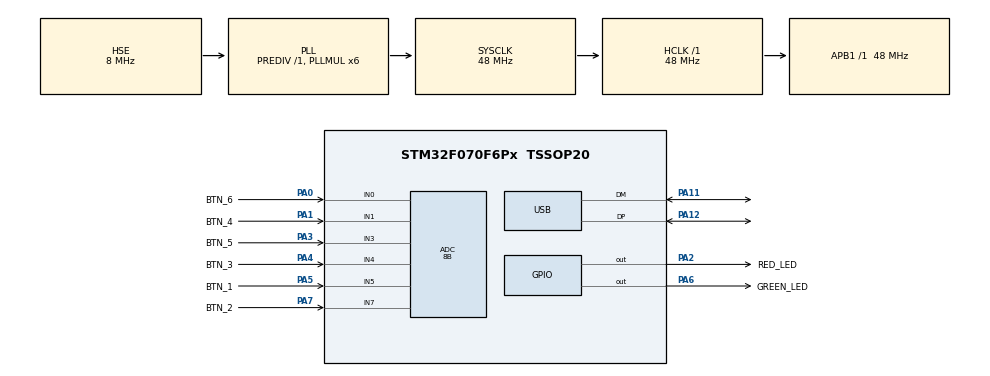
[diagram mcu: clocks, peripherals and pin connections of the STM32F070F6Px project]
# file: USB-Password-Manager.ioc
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ADC.ContinuousConvMode=ENABLE
ADC.LowPowerAutoWait=DISABLE
ADC.Resolution=ADC_RESOLUTION_8B
ADC.SamplingTime=ADC_SAMPLETIME_239CYCLES_5
Mcu.Family=STM32F0
Mcu.Name=STM32F070F6Px
Mcu.Package=TSSOP20
NVIC.USB_IRQn=true\:0\:0\:false\:false\:true\:false\:true\:true
PA0.GPIO_Label=BTN_6
PA0.Mode=IN0
PA0.Signal=ADC_IN0
PA1.GPIO_Label=BTN_4
PA1.Mode=IN1
PA1.Signal=ADC_IN1
PA11.Mode=Device
PA11.Signal=USB_DM
PA12.Mode=Device
PA12.Signal=USB_DP
PA13.Mode=Serial_Wire
PA13.Signal=SYS_SWDIO
PA14.Mode=Serial_Wire
PA14.Signal=SYS_SWCLK
PA2.GPIO_Label=RED_LED
PA2.Signal=GPIO_Output
PA3.GPIO_Label=BTN_5
PA3.Mode=IN3
PA3.Signal=ADC_IN3
PA4.GPIO_Label=BTN_3
PA4.Mode=IN4
PA4.Signal=ADC_IN4
PA5.GPIO_Label=BTN_1
PA5.Mode=IN5
PA5.Signal=ADC_IN5
PA6.GPIO_Label=GREEN_LED
PA6.Signal=GPIO_Output
PA7.GPIO_Label=BTN_2
PA7.Mode=IN7
PA7.Signal=ADC_IN7
PF0-OSC_IN.Mode=HSE-External-Oscillator
PF0-OSC_IN.Signal=RCC_OSC_IN
PF1-OSC_OUT.Mode=HSE-External-Oscillator
PF1-OSC_OUT.Signal=RCC_OSC_OUT
ProjectManager.HeapSize=0x100
ProjectManager.StackSize=0x300
ProjectManager.TargetToolchain=STM32CubeIDE
RCC.AHBFreq_Value=48000000
RCC.APB1Freq_Value=48000000
RCC.APB1TimFreq_Value=48000000
RCC.HCLKFreq_Value=48000000
RCC.PLLMUL=RCC_PLL_MUL6
RCC.PLLSourceVirtual=RCC_PLLSOURCE_HSE
RCC.PREFETCH_ENABLE=0
RCC.SYSCLKFreq_VALUE=48000000
RCC.SYSCLKSource=RCC_SYSCLKSOURCE_PLLCLK
USB_DEVICE.APP_RX_DATA_SIZE=128
USB_DEVICE.APP_TX_DATA_SIZE=128
USB_DEVICE.CLASS_NAME_FS=CDC
USB_DEVICE.USBD_MAX_STR_DESC_SIZ=64
USB_DEVICE.USBD_SELF_POWERED=0
USB_DEVICE.VirtualMode=Cdc
USB_DEVICE.VirtualModeFS=Cdc_FS
VP_SYS_VS_PINREMAP.Mode=PINREMAP
VP_USB_DEVICE_VS_USB_DEVICE_CDC_FS.Mode=CDC_FS
board=custom

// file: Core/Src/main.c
/* USER CODE BEGIN Header */
/**
  ******************************************************************************
  * @file           : main.c
  * @brief          : Main program body
  ******************************************************************************
  * @attention
  *
  * Copyright (c) 2022 STMicroelectronics.
  * All rights reserved.
  *
  * This software is licensed under terms that can be found in the LICENSE file
  * in the root directory of this software component.
  * If no LICENSE file comes with this software, it is provided AS-IS.
  *
  ******************************************************************************
  */
/* USER CODE END Header */
#include "main.h"
#include "usb_device.h"

ADC_HandleTypeDef hadc;

void SystemClock_Config(void);
static void MX_GPIO_Init(void);
static void MX_ADC_Init(void);
/* USER CODE BEGIN PFP */
extern void setup(void);
extern void loop(void);
/* USER CODE END PFP */

int main(void)
{

  /* MCU Configuration--------------------------------------------------------*/

  /* Reset of all peripherals, Initializes the Flash interface and the Systick. */
  HAL_Init();

  /* Configure the system clock */
  SystemClock_Config();

  /* Initialize all configured peripherals */
  MX_GPIO_Init();
  MX_USB_DEVICE_Init();
  MX_ADC_Init();
  /* USER CODE BEGIN 2 */
  HAL_Delay(100);
  setup();
  /* USER CODE END 2 */

  /* Infinite loop */
  while (1)
  {

    /* USER CODE BEGIN 3 */
        static uint32_t prevTick = 0u;
        uint32_t currentTick = HAL_GetTick();
        if ((uint32_t)(currentTick - prevTick) > 10u) {
            loop();
            prevTick = currentTick;
        }
  }
  /* USER CODE END 3 */
}

void SystemClock_Config(void)
{
  RCC_OscInitTypeDef RCC_OscInitStruct = {0};
  RCC_ClkInitTypeDef RCC_ClkInitStruct = {0};
  RCC_PeriphCLKInitTypeDef PeriphClkInit = {0};

  /** Initializes the RCC Oscillators according to the specified parameters
  * in the RCC_OscInitTypeDef structure.
  */
  RCC_OscInitStruct.OscillatorType = RCC_OSCILLATORTYPE_HSI14|RCC_OSCILLATORTYPE_HSE;
  RCC_OscInitStruct.HSEState = RCC_HSE_ON;
  RCC_OscInitStruct.HSI14State = RCC_HSI14_ON;
  RCC_OscInitStruct.HSI14CalibrationValue = 16;
  RCC_OscInitStruct.PLL.PLLState = RCC_PLL_ON;
  RCC_OscInitStruct.PLL.PLLSource = RCC_PLLSOURCE_HSE;
  RCC_OscInitStruct.PLL.PLLMUL = RCC_PLL_MUL6;
  RCC_OscInitStruct.PLL.PREDIV = RCC_PREDIV_DIV1;
  if (HAL_RCC_OscConfig(&RCC_OscInitStruct) != HAL_OK)
  {
    Error_Handler();
  }

  /** Initializes the CPU, AHB and APB buses clocks
  */
  RCC_ClkInitStruct.ClockType = RCC_CLOCKTYPE_HCLK|RCC_CLOCKTYPE_SYSCLK
                              |RCC_CLOCKTYPE_PCLK1;
  RCC_ClkInitStruct.SYSCLKSource = RCC_SYSCLKSOURCE_PLLCLK;
  RCC_ClkInitStruct.AHBCLKDivider = RCC_SYSCLK_DIV1;
  RCC_ClkInitStruct.APB1CLKDivider = RCC_HCLK_DIV1;

  if (HAL_RCC_ClockConfig(&RCC_ClkInitStruct, FLASH_LATENCY_1) != HAL_OK)
  {
    Error_Handler();
  }
  PeriphClkInit.PeriphClockSelection = RCC_PERIPHCLK_USB;
  PeriphClkInit.UsbClockSelection = RCC_USBCLKSOURCE_PLL;

  if (HAL_RCCEx_PeriphCLKConfig(&PeriphClkInit) != HAL_OK)
  {
    Error_Handler();
  }
}

static void MX_ADC_Init(void)
{

  ADC_ChannelConfTypeDef sConfig = {0};

  /** Configure the global features of the ADC (Clock, Resolution, Data Alignment and number of conversion)
  */
  hadc.Instance = ADC1;
  hadc.Init.ClockPrescaler = ADC_CLOCK_ASYNC_DIV1;
  hadc.Init.Resolution = ADC_RESOLUTION_8B;
  hadc.Init.DataAlign = ADC_DATAALIGN_RIGHT;
  hadc.Init.ScanConvMode = ADC_SCAN_DIRECTION_FORWARD;
  hadc.Init.EOCSelection = ADC_EOC_SINGLE_CONV;
  hadc.Init.LowPowerAutoWait = DISABLE;
  hadc.Init.LowPowerAutoPowerOff = DISABLE;
  hadc.Init.ContinuousConvMode = ENABLE;
  hadc.Init.DiscontinuousConvMode = DISABLE;
  hadc.Init.ExternalTrigConv = ADC_SOFTWARE_START;
  hadc.Init.ExternalTrigConvEdge = ADC_EXTERNALTRIGCONVEDGE_NONE;
  hadc.Init.DMAContinuousRequests = DISABLE;
  hadc.Init.Overrun = ADC_OVR_DATA_PRESERVED;
  if (HAL_ADC_Init(&hadc) != HAL_OK)
  {
    Error_Handler();
  }

  /** Configure for the selected ADC regular channel to be converted.
  */
  sConfig.Channel = ADC_CHANNEL_0;
  sConfig.Rank = ADC_RANK_CHANNEL_NUMBER;
  sConfig.SamplingTime = ADC_SAMPLETIME_239CYCLES_5;
  if (HAL_ADC_ConfigChannel(&hadc, &sConfig) != HAL_OK)
  {
    Error_Handler();
  }

  /** Configure for the selected ADC regular channel to be converted.
  */
  sConfig.Channel = ADC_CHANNEL_1;
  if (HAL_ADC_ConfigChannel(&hadc, &sConfig) != HAL_OK)
  {
    Error_Handler();
  }

  /** Configure for the selected ADC regular channel to be converted.
  */
  sConfig.Channel = ADC_CHANNEL_3;
  if (HAL_ADC_ConfigChannel(&hadc, &sConfig) != HAL_OK)
  {
    Error_Handler();
  }

  /** Configure for the selected ADC regular channel to be converted.
  */
  sConfig.Channel = ADC_CHANNEL_4;
  if (HAL_ADC_ConfigChannel(&hadc, &sConfig) != HAL_OK)
  {
    Error_Handler();
  }

  /** Configure for the selected ADC regular channel to be converted.
  */
  sConfig.Channel = ADC_CHANNEL_5;
  if (HAL_ADC_ConfigChannel(&hadc, &sConfig) != HAL_OK)
  {
    Error_Handler();
  }

  /** Configure for the selected ADC regular channel to be converted.
  */
  sConfig.Channel = ADC_CHANNEL_7;
  if (HAL_ADC_ConfigChannel(&hadc, &sConfig) != HAL_OK)
  {
    Error_Handler();
  }

}

static void MX_GPIO_Init(void)
{
  GPIO_InitTypeDef GPIO_InitStruct = {0};

  /* GPIO Ports Clock Enable */
  __HAL_RCC_GPIOF_CLK_ENABLE();
  __HAL_RCC_GPIOA_CLK_ENABLE();

  /*Configure GPIO pin Output Level */
  HAL_GPIO_WritePin(GPIOA, RED_LED_Pin|GREEN_LED_Pin, GPIO_PIN_RESET);

  /*Configure GPIO pins : RED_LED_Pin GREEN_LED_Pin */
  GPIO_InitStruct.Pin = RED_LED_Pin|GREEN_LED_Pin;
  GPIO_InitStruct.Mode = GPIO_MODE_OUTPUT_PP;
  GPIO_InitStruct.Pull = GPIO_NOPULL;
  GPIO_InitStruct.Speed = GPIO_SPEED_FREQ_LOW;
  HAL_GPIO_Init(GPIOA, &GPIO_InitStruct);

}

void Error_Handler(void)
{
  __disable_irq();
  while (1)
  {
  }
}
